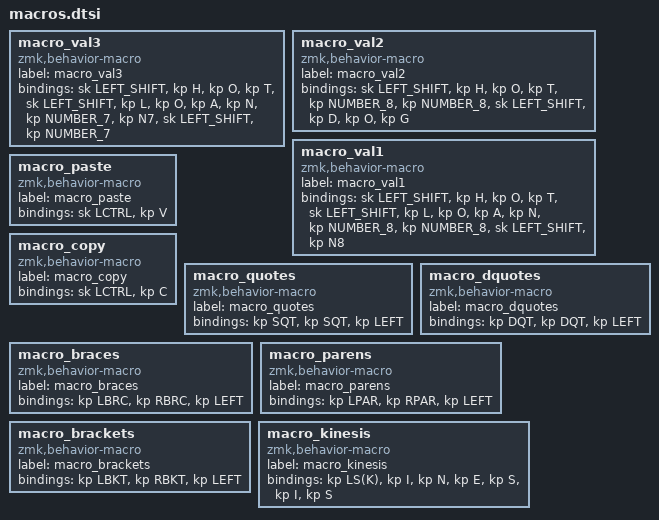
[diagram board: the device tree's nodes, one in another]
macro_val3: macro_val3{
compatible = "zmk,behavior-macro";
label = "macro_val3";
#binding-cells = <0>;
bindings = <&sk LEFT_SHIFT>, <&kp H>, <&kp O>, <&kp T>, <&sk LEFT_SHIFT>, <&kp L>, <&kp O>, <&kp A>, <&kp N>, <&kp NUMBER_7>, <&kp N7>, <&sk LEFT_SHIFT>, <&kp NUMBER_7>;
};
macro_val2: macro_val2{
compatible = "zmk,behavior-macro";
label = "macro_val2";
#binding-cells = <0>;
bindings = <&sk LEFT_SHIFT>, <&kp H>, <&kp O>, <&kp T>, <&kp NUMBER_8>, <&kp NUMBER_8>, <&sk LEFT_SHIFT>, <&kp D>, <&kp O>, <&kp G>;
};
macro_val1: macro_val1{
compatible = "zmk,behavior-macro";
label = "macro_val1";
#binding-cells = <0>;
bindings = <&sk LEFT_SHIFT>, <&kp H>, <&kp O>, <&kp T>, <&sk LEFT_SHIFT>, <&kp L>, <&kp O>, <&kp A>, <&kp N>, <&kp NUMBER_8>, <&kp NUMBER_8>, <&sk LEFT_SHIFT>, <&kp N8>;
};
macro_paste: macro_paste{
compatible = "zmk,behavior-macro";
label = "macro_paste";
#binding-cells = <0>;
bindings = <&sk LCTRL>, <&kp V>;
};
macro_copy: macro_copy{
compatible = "zmk,behavior-macro";
label = "macro_copy";
#binding-cells = <0>;
bindings = <&sk LCTRL>, <&kp C>;
};
macro_quotes: macro_quotes{
compatible = "zmk,behavior-macro";
label = "macro_quotes";
#binding-cells = <0>;
bindings = <&kp SQT>, <&kp SQT>, <&kp LEFT>;
};
macro_dquotes: macro_dquotes{
compatible = "zmk,behavior-macro";
label = "macro_dquotes";
#binding-cells = <0>;
bindings = <&kp DQT>, <&kp DQT>, <&kp LEFT>;
};
macro_braces: macro_braces{
compatible = "zmk,behavior-macro";
label = "macro_braces";
#binding-cells = <0>;
bindings = <&kp LBRC>, <&kp RBRC>, <&kp LEFT>;
};
macro_parens: macro_parens{
compatible = "zmk,behavior-macro";
label = "macro_parens";
#binding-cells = <0>;
bindings = <&kp LPAR>, <&kp RPAR>, <&kp LEFT>;
};
macro_brackets: macro_brackets{
compatible = "zmk,behavior-macro";
label = "macro_brackets";
#binding-cells = <0>;
bindings = <&kp LBKT>, <&kp RBKT>, <&kp LEFT>;
};
macro_kinesis: macro_kinesis{
compatible = "zmk,behavior-macro";
label = "macro_kinesis";
#binding-cells = <0>;
bindings = <&kp LS(K)>, <&kp I>, <&kp N>, <&kp E>, <&kp S>, <&kp I>, <&kp S>;
};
